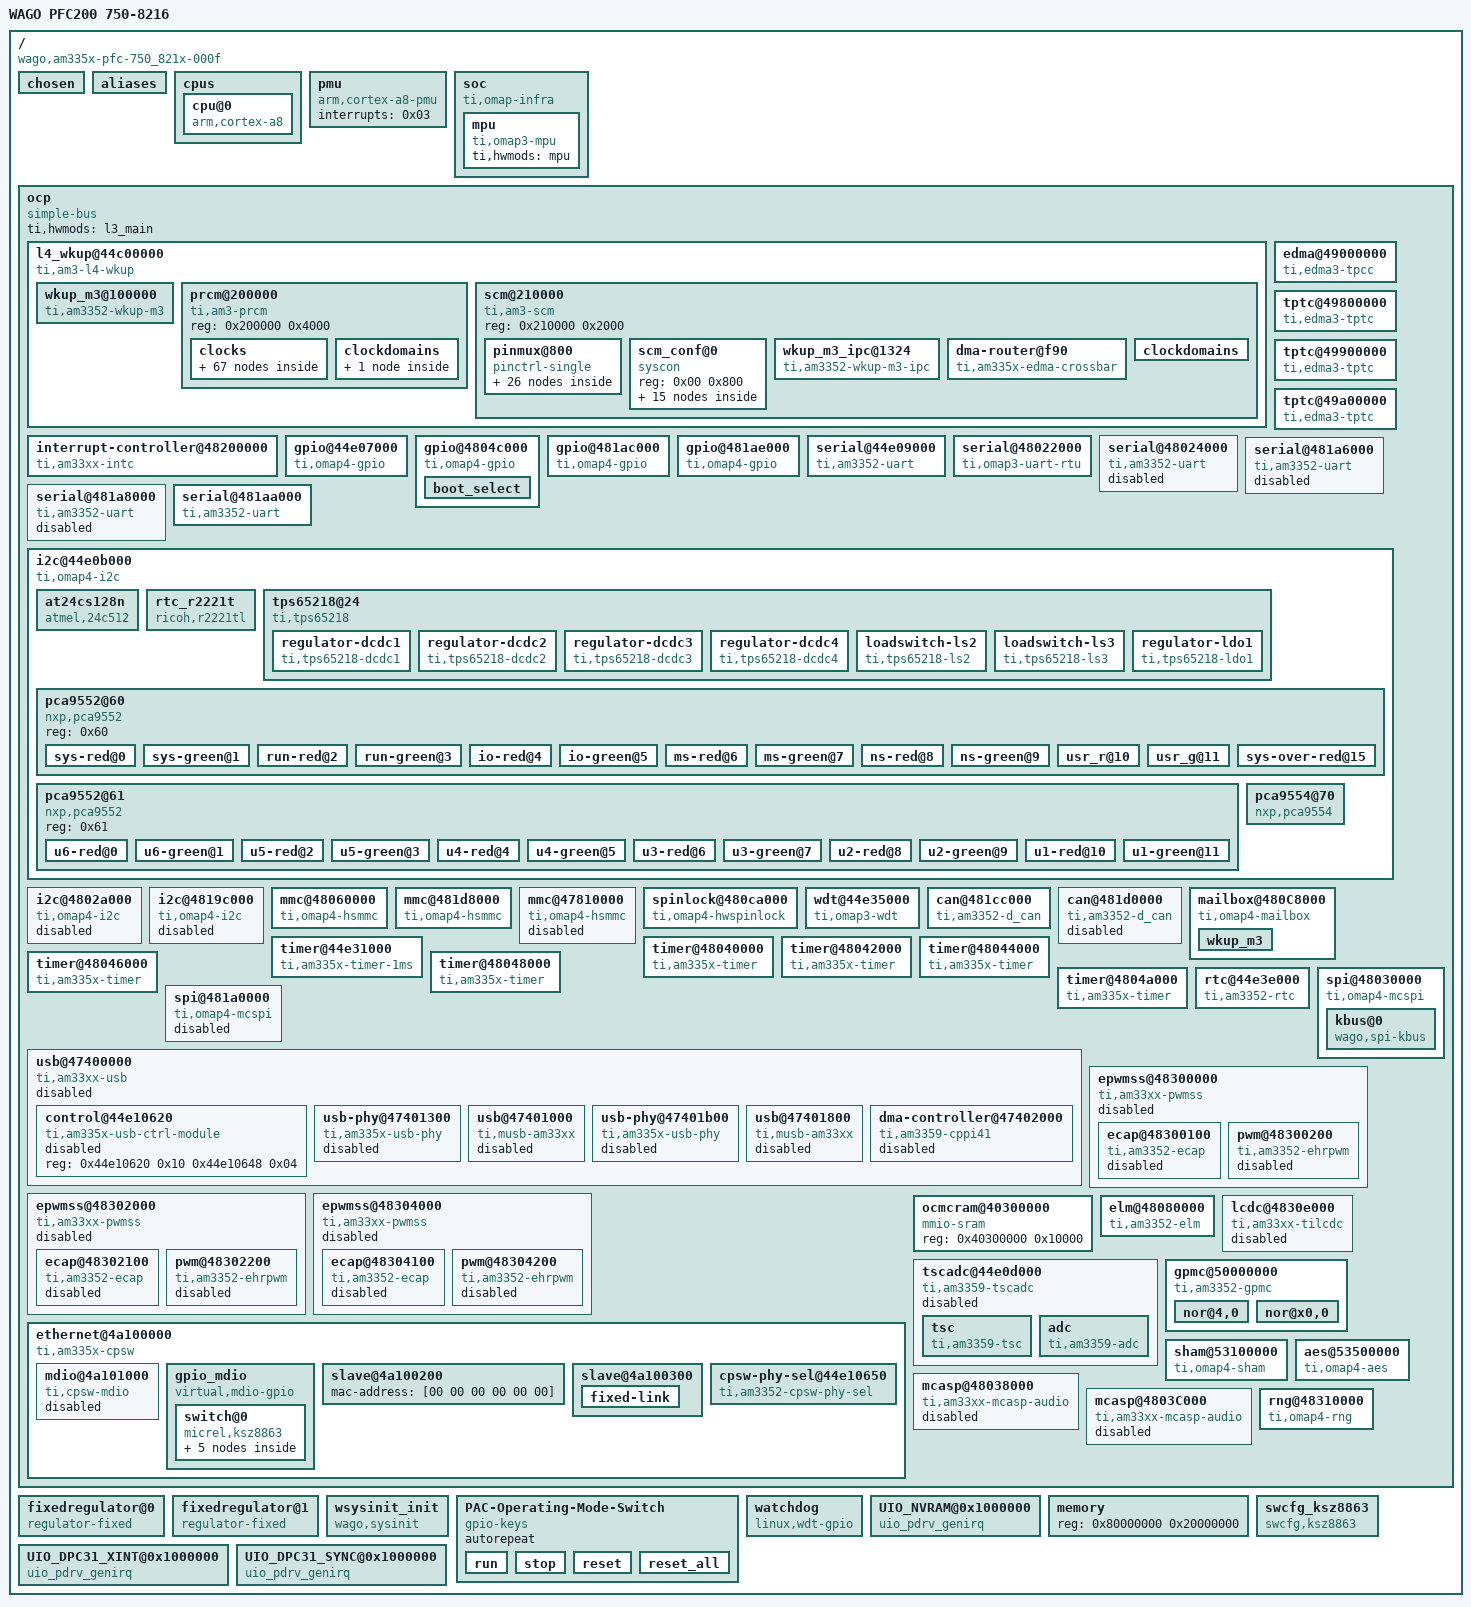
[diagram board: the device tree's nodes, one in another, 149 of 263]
/dts-v1/;

/ {
	compatible = "wago,am335x-pfc-750_821x-000f\0wago,am335x-pfc\0ti,am33xx";
	interrupt-parent = <0x01>;
	#address-cells = <0x01>;
	#size-cells = <0x01>;
	model = "WAGO PFC200 750-8216";

	chosen {
	};

	aliases {
		i2c0 = "/ocp/i2c@44e0b000";
		i2c1 = "/ocp/i2c@4802a000";
		i2c2 = "/ocp/i2c@4819c000";
		serial0 = "/ocp/serial@44e09000";
		serial1 = "/ocp/serial@48022000";
		serial2 = "/ocp/serial@48024000";
		serial3 = "/ocp/serial@481a6000";
		serial4 = "/ocp/serial@481a8000";
		serial5 = "/ocp/serial@481aa000";
		d_can0 = "/ocp/can@481cc000";
		d_can1 = "/ocp/can@481d0000";
		usb0 = "/ocp/usb@47400000/usb@47401000";
		usb1 = "/ocp/usb@47400000/usb@47401800";
		phy0 = "/ocp/usb@47400000/usb-phy@47401300";
		phy1 = "/ocp/usb@47400000/usb-phy@47401b00";
		ethernet0 = "/ocp/ethernet@4a100000/slave@4a100200";
		ethernet1 = "/ocp/ethernet@4a100000/slave@4a100300";
		mdio-gpio0 = "/ocp/ethernet@4a100000/gpio_mdio";
	};

	cpus {
		#address-cells = <0x01>;
		#size-cells = <0x00>;

		cpu@0 {
			compatible = "arm,cortex-a8";
			device_type = "cpu";
			reg = <0x00>;
			operating-points = <0xf4240 0x1437c8 0xc3500 0x1339e0 0xafc80 0x124f80 0x927c0 0x10c8e0 0x493e0 0xe7ef0>;
			voltage-tolerance = <0x02>;
			clocks = <0x02>;
			clock-names = "cpu";
			clock-latency = <0x493e0>;
			cpu0-supply = <0x03>;
		};
	};

	pmu {
		compatible = "arm,cortex-a8-pmu";
		interrupts = <0x03>;
	};

	soc {
		compatible = "ti,omap-infra";

		mpu {
			compatible = "ti,omap3-mpu";
			ti,hwmods = "mpu";
		};
	};

	ocp {
		compatible = "simple-bus";
		#address-cells = <0x01>;
		#size-cells = <0x01>;
		ranges;
		ti,hwmods = "l3_main";

		l4_wkup@44c00000 {
			compatible = "ti,am3-l4-wkup\0simple-bus";
			#address-cells = <0x01>;
			#size-cells = <0x01>;
			ranges = <0x00 0x44c00000 0x280000>;

			wkup_m3@100000 {
				compatible = "ti,am3352-wkup-m3";
				reg = <0x100000 0x4000 0x180000 0x2000>;
				reg-names = "umem\0dmem";
				ti,hwmods = "wkup_m3";
				ti,pm-firmware = "am335x-pm-firmware.elf";
				linux,phandle = <0x27>;
				phandle = <0x27>;
			};

			prcm@200000 {
				compatible = "ti,am3-prcm";
				reg = <0x200000 0x4000>;

				clocks {
					#address-cells = <0x01>;
					#size-cells = <0x00>;

					clk_32768_ck {
						#clock-cells = <0x00>;
						compatible = "fixed-clock";
						clock-frequency = <0x8000>;
						linux,phandle = <0x14>;
						phandle = <0x14>;
					};

					clk_rc32k_ck {
						#clock-cells = <0x00>;
						compatible = "fixed-clock";
						clock-frequency = <0x7d00>;
						linux,phandle = <0x13>;
						phandle = <0x13>;
					};

					virt_19200000_ck {
						#clock-cells = <0x00>;
						compatible = "fixed-clock";
						clock-frequency = <0x124f800>;
						linux,phandle = <0x22>;
						phandle = <0x22>;
					};

					virt_24000000_ck {
						#clock-cells = <0x00>;
						compatible = "fixed-clock";
						clock-frequency = <0x16e3600>;
						linux,phandle = <0x23>;
						phandle = <0x23>;
					};

					virt_25000000_ck {
						#clock-cells = <0x00>;
						compatible = "fixed-clock";
						clock-frequency = <0x17d7840>;
						linux,phandle = <0x24>;
						phandle = <0x24>;
					};

					virt_26000000_ck {
						#clock-cells = <0x00>;
						compatible = "fixed-clock";
						clock-frequency = <0x18cba80>;
						linux,phandle = <0x25>;
						phandle = <0x25>;
					};

					tclkin_ck {
						#clock-cells = <0x00>;
						compatible = "fixed-clock";
						clock-frequency = <0xb71b00>;
						linux,phandle = <0x12>;
						phandle = <0x12>;
					};

					dpll_core_ck@490 {
						#clock-cells = <0x00>;
						compatible = "ti,am3-dpll-core-clock";
						clocks = <0x04 0x04>;
						reg = <0x490 0x45c 0x468>;
						linux,phandle = <0x05>;
						phandle = <0x05>;
					};

					dpll_core_x2_ck {
						#clock-cells = <0x00>;
						compatible = "ti,am3-dpll-x2-clock";
						clocks = <0x05>;
						linux,phandle = <0x06>;
						phandle = <0x06>;
					};

					dpll_core_m4_ck@480 {
						#clock-cells = <0x00>;
						compatible = "ti,divider-clock";
						clocks = <0x06>;
						ti,max-div = <0x1f>;
						reg = <0x480>;
						ti,index-starts-at-one;
						linux,phandle = <0x0e>;
						phandle = <0x0e>;
					};

					dpll_core_m5_ck@484 {
						#clock-cells = <0x00>;
						compatible = "ti,divider-clock";
						clocks = <0x06>;
						ti,max-div = <0x1f>;
						reg = <0x484>;
						ti,index-starts-at-one;
						linux,phandle = <0x16>;
						phandle = <0x16>;
					};

					dpll_core_m6_ck@4d8 {
						#clock-cells = <0x00>;
						compatible = "ti,divider-clock";
						clocks = <0x06>;
						ti,max-div = <0x1f>;
						reg = <0x4d8>;
						ti,index-starts-at-one;
					};

					dpll_mpu_ck@488 {
						#clock-cells = <0x00>;
						compatible = "ti,am3-dpll-clock";
						clocks = <0x04 0x04>;
						reg = <0x488 0x420 0x42c>;
						linux,phandle = <0x02>;
						phandle = <0x02>;
					};

					dpll_mpu_m2_ck@4a8 {
						#clock-cells = <0x00>;
						compatible = "ti,divider-clock";
						clocks = <0x02>;
						ti,max-div = <0x1f>;
						reg = <0x4a8>;
						ti,index-starts-at-one;
					};

					dpll_ddr_ck@494 {
						#clock-cells = <0x00>;
						compatible = "ti,am3-dpll-no-gate-clock";
						clocks = <0x04 0x04>;
						reg = <0x494 0x434 0x440>;
						linux,phandle = <0x07>;
						phandle = <0x07>;
					};

					dpll_ddr_m2_ck@4a0 {
						#clock-cells = <0x00>;
						compatible = "ti,divider-clock";
						clocks = <0x07>;
						ti,max-div = <0x1f>;
						reg = <0x4a0>;
						ti,index-starts-at-one;
						linux,phandle = <0x08>;
						phandle = <0x08>;
					};

					dpll_ddr_m2_div2_ck {
						#clock-cells = <0x00>;
						compatible = "fixed-factor-clock";
						clocks = <0x08>;
						clock-mult = <0x01>;
						clock-div = <0x02>;
					};

					dpll_disp_ck@498 {
						#clock-cells = <0x00>;
						compatible = "ti,am3-dpll-no-gate-clock";
						clocks = <0x04 0x04>;
						reg = <0x498 0x448 0x454>;
						linux,phandle = <0x09>;
						phandle = <0x09>;
					};

					dpll_disp_m2_ck@4a4 {
						#clock-cells = <0x00>;
						compatible = "ti,divider-clock";
						clocks = <0x09>;
						ti,max-div = <0x1f>;
						reg = <0x4a4>;
						ti,index-starts-at-one;
						ti,set-rate-parent;
						linux,phandle = <0x10>;
						phandle = <0x10>;
					};

					dpll_per_ck@48c {
						#clock-cells = <0x00>;
						compatible = "ti,am3-dpll-no-gate-j-type-clock";
						clocks = <0x04 0x04>;
						reg = <0x48c 0x470 0x49c>;
						linux,phandle = <0x0a>;
						phandle = <0x0a>;
					};

					dpll_per_m2_ck@4ac {
						#clock-cells = <0x00>;
						compatible = "ti,divider-clock";
						clocks = <0x0a>;
						ti,max-div = <0x1f>;
						reg = <0x4ac>;
						ti,index-starts-at-one;
						linux,phandle = <0x0b>;
						phandle = <0x0b>;
					};

					dpll_per_m2_div4_wkupdm_ck {
						#clock-cells = <0x00>;
						compatible = "fixed-factor-clock";
						clocks = <0x0b>;
						clock-mult = <0x01>;
						clock-div = <0x04>;
					};

					dpll_per_m2_div4_ck {
						#clock-cells = <0x00>;
						compatible = "fixed-factor-clock";
						clocks = <0x0b>;
						clock-mult = <0x01>;
						clock-div = <0x04>;
					};

					cefuse_fck@a20 {
						#clock-cells = <0x00>;
						compatible = "ti,gate-clock";
						clocks = <0x04>;
						ti,bit-shift = <0x01>;
						reg = <0xa20>;
					};

					clk_24mhz {
						#clock-cells = <0x00>;
						compatible = "fixed-factor-clock";
						clocks = <0x0b>;
						clock-mult = <0x01>;
						clock-div = <0x08>;
						linux,phandle = <0x0c>;
						phandle = <0x0c>;
					};

					clkdiv32k_ck {
						#clock-cells = <0x00>;
						compatible = "fixed-factor-clock";
						clocks = <0x0c>;
						clock-mult = <0x01>;
						clock-div = <0x2dc>;
						linux,phandle = <0x0d>;
						phandle = <0x0d>;
					};

					clkdiv32k_ick@14c {
						#clock-cells = <0x00>;
						compatible = "ti,gate-clock";
						clocks = <0x0d>;
						ti,bit-shift = <0x01>;
						reg = <0x14c>;
						linux,phandle = <0x11>;
						phandle = <0x11>;
					};

					l3_gclk {
						#clock-cells = <0x00>;
						compatible = "fixed-factor-clock";
						clocks = <0x0e>;
						clock-mult = <0x01>;
						clock-div = <0x01>;
						linux,phandle = <0x0f>;
						phandle = <0x0f>;
					};

					pruss_ocp_gclk@530 {
						#clock-cells = <0x00>;
						compatible = "ti,mux-clock";
						clocks = <0x0f 0x10>;
						reg = <0x530>;
					};

					mmu_fck@914 {
						#clock-cells = <0x00>;
						compatible = "ti,gate-clock";
						clocks = <0x0e>;
						ti,bit-shift = <0x01>;
						reg = <0x914>;
					};

					timer1_fck@528 {
						#clock-cells = <0x00>;
						compatible = "ti,mux-clock";
						clocks = <0x04 0x11 0x12 0x13 0x14>;
						reg = <0x528>;
					};

					timer2_fck@508 {
						#clock-cells = <0x00>;
						compatible = "ti,mux-clock";
						clocks = <0x12 0x04 0x11>;
						reg = <0x508>;
					};

					timer3_fck@50c {
						#clock-cells = <0x00>;
						compatible = "ti,mux-clock";
						clocks = <0x12 0x04 0x11>;
						reg = <0x50c>;
					};

					timer4_fck@510 {
						#clock-cells = <0x00>;
						compatible = "ti,mux-clock";
						clocks = <0x12 0x04 0x11>;
						reg = <0x510>;
					};

					timer5_fck@518 {
						#clock-cells = <0x00>;
						compatible = "ti,mux-clock";
						clocks = <0x12 0x04 0x11>;
						reg = <0x518>;
					};

					timer6_fck@51c {
						#clock-cells = <0x00>;
						compatible = "ti,mux-clock";
						clocks = <0x12 0x04 0x11>;
						reg = <0x51c>;
					};

					timer7_fck@504 {
						#clock-cells = <0x00>;
						compatible = "ti,mux-clock";
						clocks = <0x12 0x04 0x11>;
						reg = <0x504>;
					};

					usbotg_fck@47c {
						#clock-cells = <0x00>;
						compatible = "ti,gate-clock";
						clocks = <0x0a>;
						ti,bit-shift = <0x08>;
						reg = <0x47c>;
					};

					dpll_core_m4_div2_ck {
						#clock-cells = <0x00>;
						compatible = "fixed-factor-clock";
						clocks = <0x0e>;
						clock-mult = <0x01>;
						clock-div = <0x02>;
						linux,phandle = <0x15>;
						phandle = <0x15>;
					};

					ieee5000_fck@e4 {
						#clock-cells = <0x00>;
						compatible = "ti,gate-clock";
						clocks = <0x15>;
						ti,bit-shift = <0x01>;
						reg = <0xe4>;
					};

					wdt1_fck@538 {
						#clock-cells = <0x00>;
						compatible = "ti,mux-clock";
						clocks = <0x13 0x11>;
						reg = <0x538>;
					};

					l4_rtc_gclk {
						#clock-cells = <0x00>;
						compatible = "fixed-factor-clock";
						clocks = <0x0e>;
						clock-mult = <0x01>;
						clock-div = <0x02>;
					};

					l4hs_gclk {
						#clock-cells = <0x00>;
						compatible = "fixed-factor-clock";
						clocks = <0x0e>;
						clock-mult = <0x01>;
						clock-div = <0x01>;
					};

					l3s_gclk {
						#clock-cells = <0x00>;
						compatible = "fixed-factor-clock";
						clocks = <0x15>;
						clock-mult = <0x01>;
						clock-div = <0x01>;
					};

					l4fw_gclk {
						#clock-cells = <0x00>;
						compatible = "fixed-factor-clock";
						clocks = <0x15>;
						clock-mult = <0x01>;
						clock-div = <0x01>;
					};

					l4ls_gclk {
						#clock-cells = <0x00>;
						compatible = "fixed-factor-clock";
						clocks = <0x15>;
						clock-mult = <0x01>;
						clock-div = <0x01>;
						linux,phandle = <0x26>;
						phandle = <0x26>;
					};

					sysclk_div_ck {
						#clock-cells = <0x00>;
						compatible = "fixed-factor-clock";
						clocks = <0x0e>;
						clock-mult = <0x01>;
						clock-div = <0x01>;
					};

					cpsw_125mhz_gclk {
						#clock-cells = <0x00>;
						compatible = "fixed-factor-clock";
						clocks = <0x16>;
						clock-mult = <0x01>;
						clock-div = <0x02>;
						linux,phandle = <0x4a>;
						phandle = <0x4a>;
					};

					cpsw_cpts_rft_clk@520 {
						#clock-cells = <0x00>;
						compatible = "ti,mux-clock";
						clocks = <0x16 0x0e>;
						reg = <0x520>;
						linux,phandle = <0x4b>;
						phandle = <0x4b>;
					};

					gpio0_dbclk_mux_ck@53c {
						#clock-cells = <0x00>;
						compatible = "ti,mux-clock";
						clocks = <0x13 0x14 0x11>;
						reg = <0x53c>;
						linux,phandle = <0x17>;
						phandle = <0x17>;
					};

					gpio0_dbclk@408 {
						#clock-cells = <0x00>;
						compatible = "ti,gate-clock";
						clocks = <0x17>;
						ti,bit-shift = <0x12>;
						reg = <0x408>;
					};

					gpio1_dbclk@ac {
						#clock-cells = <0x00>;
						compatible = "ti,gate-clock";
						clocks = <0x11>;
						ti,bit-shift = <0x12>;
						reg = <0xac>;
					};

					gpio2_dbclk@b0 {
						#clock-cells = <0x00>;
						compatible = "ti,gate-clock";
						clocks = <0x11>;
						ti,bit-shift = <0x12>;
						reg = <0xb0>;
					};

					gpio3_dbclk@b4 {
						#clock-cells = <0x00>;
						compatible = "ti,gate-clock";
						clocks = <0x11>;
						ti,bit-shift = <0x12>;
						reg = <0xb4>;
					};

					lcd_gclk@534 {
						#clock-cells = <0x00>;
						compatible = "ti,mux-clock";
						clocks = <0x10 0x16 0x0b>;
						reg = <0x534>;
						ti,set-rate-parent;
						linux,phandle = <0x19>;
						phandle = <0x19>;
					};

					mmc_clk {
						#clock-cells = <0x00>;
						compatible = "fixed-factor-clock";
						clocks = <0x0b>;
						clock-mult = <0x01>;
						clock-div = <0x02>;
					};

					gfx_fclk_clksel_ck@52c {
						#clock-cells = <0x00>;
						compatible = "ti,mux-clock";
						clocks = <0x0e 0x0b>;
						ti,bit-shift = <0x01>;
						reg = <0x52c>;
						linux,phandle = <0x18>;
						phandle = <0x18>;
					};

					gfx_fck_div_ck@52c {
						#clock-cells = <0x00>;
						compatible = "ti,divider-clock";
						clocks = <0x18>;
						reg = <0x52c>;
						ti,max-div = <0x02>;
					};

					sysclkout_pre_ck@700 {
						#clock-cells = <0x00>;
						compatible = "ti,mux-clock";
						clocks = <0x14 0x0f 0x08 0x0b 0x19>;
						reg = <0x700>;
						linux,phandle = <0x1a>;
						phandle = <0x1a>;
					};

					clkout2_div_ck@700 {
						#clock-cells = <0x00>;
						compatible = "ti,divider-clock";
						clocks = <0x1a>;
						ti,bit-shift = <0x03>;
						ti,max-div = <0x08>;
						reg = <0x700>;
						linux,phandle = <0x1f>;
						phandle = <0x1f>;
					};

					dbg_sysclk_ck@414 {
						#clock-cells = <0x00>;
						compatible = "ti,gate-clock";
						clocks = <0x04>;
						ti,bit-shift = <0x13>;
						reg = <0x414>;
						linux,phandle = <0x1b>;
						phandle = <0x1b>;
					};

					dbg_clka_ck@414 {
						#clock-cells = <0x00>;
						compatible = "ti,gate-clock";
						clocks = <0x0e>;
						ti,bit-shift = <0x1e>;
						reg = <0x414>;
						linux,phandle = <0x1c>;
						phandle = <0x1c>;
					};

					stm_pmd_clock_mux_ck@414 {
						#clock-cells = <0x00>;
						compatible = "ti,mux-clock";
						clocks = <0x1b 0x1c>;
						ti,bit-shift = <0x16>;
						reg = <0x414>;
						linux,phandle = <0x1d>;
						phandle = <0x1d>;
					};

					trace_pmd_clk_mux_ck@414 {
						#clock-cells = <0x00>;
						compatible = "ti,mux-clock";
						clocks = <0x1b 0x1c>;
						ti,bit-shift = <0x14>;
						reg = <0x414>;
						linux,phandle = <0x1e>;
						phandle = <0x1e>;
					};

					stm_clk_div_ck@414 {
						#clock-cells = <0x00>;
						compatible = "ti,divider-clock";
						clocks = <0x1d>;
						ti,bit-shift = <0x1b>;
						ti,max-div = <0x40>;
						reg = <0x414>;
						ti,index-power-of-two;
					};

					trace_clk_div_ck@414 {
						#clock-cells = <0x00>;
						compatible = "ti,divider-clock";
						clocks = <0x1e>;
						ti,bit-shift = <0x18>;
						ti,max-div = <0x40>;
						reg = <0x414>;
						ti,index-power-of-two;
					};

					clkout2_ck@700 {
						#clock-cells = <0x00>;
						compatible = "ti,gate-clock";
						clocks = <0x1f>;
						ti,bit-shift = <0x07>;
						reg = <0x700>;
					};
				};

				clockdomains {

					clk_24mhz_clkdm {
						compatible = "ti,clockdomain";
						clocks = <0x11>;
					};
				};
			};

			scm@210000 {
				compatible = "ti,am3-scm\0simple-bus";
				reg = <0x210000 0x2000>;
				#address-cells = <0x01>;
				#size-cells = <0x01>;
				ranges = <0x00 0x210000 0x2000>;

				pinmux@800 {
					compatible = "pinctrl-single";
					reg = <0x800 0x238>;
					#address-cells = <0x01>;
					#size-cells = <0x00>;
					pinctrl-single,register-width = <0x20>;
					pinctrl-single,function-mask = <0x7f>;
					pinctrl-names = "default";
					pinctrl-0 = <0x20 0x21>;

					pinmux_uart0_pins {
						pinctrl-single,pins = <0x170 0x30 0x174 0x50>;
						linux,phandle = <0x2f>;
						phandle = <0x2f>;
					};

					pinmux_spi0_pins {
						pinctrl-single,pins = <0x150 0x60 0x154 0x28 0x158 0x40 0x15c 0x50>;
						linux,phandle = <0x3f>;
						phandle = <0x3f>;
					};

					pinmux_i2c0_pins {
						pinctrl-single,pins = <0x188 0x70 0x18c 0x70>;
						linux,phandle = <0x33>;
						phandle = <0x33>;
					};

					pinmux_gpio_bitbang_mdio_pins {
						pinctrl-single,pins = <0x148 0x37 0x14c 0x17>;
						linux,phandle = <0x50>;
						phandle = <0x50>;
					};

					pinmux_gpio_bitbang_mdio_sleep_pins {
						pinctrl-single,pins = <0x148 0x37 0x14c 0x27>;
						linux,phandle = <0x51>;
						phandle = <0x51>;
					};

					pinmux_gpio3_pins {
						pinctrl-single,pins = <0x194 0x2f 0x198 0x2f 0x19c 0x2f 0x1a0 0x2f 0x1a8 0x37 0x1ac 0x37>;
						linux,phandle = <0x2e>;
						phandle = <0x2e>;
					};

					pinmux_mmc1_pins {
						pinctrl-single,pins = <0x100 0x30 0x104 0x30 0xfc 0x30 0xf8 0x30 0xf4 0x30 0xf0 0x30>;
						linux,phandle = <0x35>;
						phandle = <0x35>;
					};

					pinmux_watchdog_pins {
						pinctrl-single,pins = <0x1e8 0x07>;
						linux,phandle = <0x57>;
						phandle = <0x57>;
					};

					pinmux_uart1_pins {
						pinctrl-single,pins = <0x184 0x48 0x180 0x28 0x178 0x28 0x17c 0x48 0x1a4 0x47>;
						linux,phandle = <0x30>;
						phandle = <0x30>;
					};

					pinmux_uart5_pins {
						pinctrl-single,pins = <0x118 0x4b 0xd8 0x34>;
						linux,phandle = <0x32>;
						phandle = <0x32>;
					};

					pinmux_spi1_pins {
						pinctrl-single,pins = <0x168 0x2c 0x16c 0x44 0x190 0x63 0x164 0x52>;
					};

					pinmux_sdcard_cd_pins {
						pinctrl-single,pins = <0x4c 0x37>;
						linux,phandle = <0x36>;
						phandle = <0x36>;
					};

					pinmux_sdcard_wp_pins {
						pinctrl-single,pins = <0x90 0x37>;
						linux,phandle = <0x37>;
						phandle = <0x37>;
					};

					pinmux_emmc_pins {
						pinctrl-single,pins = <0x80 0x32 0x84 0x32 0x12c 0x34 0x130 0x34 0x134 0x34 0x138 0x34>;
						linux,phandle = <0x3a>;
						phandle = <0x3a>;
					};

					pinmux_gpmc_data_pins {
						pinctrl-single,pins = <0x00 0x60 0x04 0x60 0x08 0x60 0x0c 0x60 0x10 0x60 0x14 0x60 0x18 0x60 0x1c 0x60 0x20 0x60 0x24 0x60 0x28 0x60 0x2c 0x60 0x30 0x60 0x34 0x60 0x38 0x60 0x3c 0x60>;
						linux,phandle = <0x53>;
						phandle = <0x53>;
					};

					pinmux_gpmc_addr_pins {
						pinctrl-single,pins = <0xa0 0x41 0xa4 0x41 0xa8 0x41 0xac 0x41 0xb0 0x41 0xb4 0x41 0xb8 0x41 0xbc 0x41 0xe0 0x41 0xe4 0x41 0xe8 0x41 0xec 0x41 0xc0 0x41 0xc4 0x41 0xc8 0x41 0xcc 0x41 0xd0 0x41 0xd4 0x41>;
						linux,phandle = <0x54>;
						phandle = <0x54>;
					};

					pinmux_gpmc_ctrl_pins {
						pinctrl-single,pins = <0x94 0x50 0x98 0x50 0x70 0x52 0x9c 0x50 0x78 0x50 0x8c 0x32>;
						linux,phandle = <0x55>;
						phandle = <0x55>;
					};

					pinmux_rmii2_pins {
						pinctrl-single,pins = <0x40 0x0b 0x50 0x0b 0x54 0x0b 0x68 0x2b 0x6c 0x2b 0x108 0x29 0x88 0x2a>;
						linux,phandle = <0x4c>;
						phandle = <0x4c>;
					};

					pinmux_rmii2_sleep_pins {
						pinctrl-single,pins = <0x40 0x0b 0x50 0x0b 0x54 0x0b 0x68 0x2b 0x6c 0x2b 0x108 0x29 0x88 0x2a>;
						linux,phandle = <0x4e>;
						phandle = <0x4e>;
					};

					pinmux_rmii1_pins {
						pinctrl-single,pins = <0x144 0x2f 0x114 0x2f 0x128 0x2f 0x124 0x2f 0x140 0x2f 0x13c 0x2f 0x10c 0x2f>;
						linux,phandle = <0x4d>;
						phandle = <0x4d>;
					};

					pinmux_rmii1_sleep_pins {
						pinctrl-single,pins = <0x144 0x2f 0x114 0x2f 0x128 0x2f 0x124 0x2f 0x140 0x2f 0x13c 0x2f 0x10c 0x2f>;
						linux,phandle = <0x4f>;
						phandle = <0x4f>;
					};

					pinmux_kbus_pins {
						pinctrl-single,pins = <0x58 0x37 0x5c 0x37 0x1b4 0x37 0x1e4 0x57 0x60 0x37>;
						linux,phandle = <0x40>;
						phandle = <0x40>;
					};

					pinmux_gpio0_pins {
						pinctrl-single,pins = <0x1b0 0x57>;
						linux,phandle = <0x20>;
						phandle = <0x20>;
					};

					pinmux_gpio1_pins {
						pinctrl-single,pins = <0x44 0x37 0x48 0x57>;
						linux,phandle = <0x21>;
						phandle = <0x21>;
					};

					pinmux_dcan0_pins {
						pinctrl-single,pins = <0x11c 0x01 0x120 0x21>;
						linux,phandle = <0x3d>;
						phandle = <0x3d>;
					};

					pinmux_dpc31_pins {
						pinctrl-single,pins = <0x160 0x2f 0x7c 0x08 0x64 0x2f>;
						linux,phandle = <0x56>;
						phandle = <0x56>;
					};
				};

				scm_conf@0 {
					compatible = "syscon\0simple-bus";
					reg = <0x00 0x800>;
					#address-cells = <0x01>;
					#size-cells = <0x01>;
					ranges = <0x00 0x00 0x800>;
					linux,phandle = <0x3c>;
					phandle = <0x3c>;

					clocks {
						#address-cells = <0x01>;
						#size-cells = <0x00>;

						sys_clkin_ck@40 {
							#clock-cells = <0x00>;
							compatible = "ti,mux-clock";
							clocks = <0x22 0x23 0x24 0x25>;
							ti,bit-shift = <0x16>;
							reg = <0x40>;
							linux,phandle = <0x04>;
							phandle = <0x04>;
						};

						adc_tsc_fck {
							#clock-cells = <0x00>;
							compatible = "fixed-factor-clock";
							clocks = <0x04>;
							clock-mult = <0x01>;
							clock-div = <0x01>;
						};

						dcan0_fck {
							#clock-cells = <0x00>;
							compatible = "fixed-factor-clock";
							clocks = <0x04>;
							clock-mult = <0x01>;
							clock-div = <0x01>;
							linux,phandle = <0x3b>;
							phandle = <0x3b>;
						};

						dcan1_fck {
							#clock-cells = <0x00>;
							compatible = "fixed-factor-clock";
							clocks = <0x04>;
							clock-mult = <0x01>;
							clock-div = <0x01>;
							linux,phandle = <0x3e>;
							phandle = <0x3e>;
						};

						mcasp0_fck {
							#clock-cells = <0x00>;
							compatible = "fixed-factor-clock";
							clocks = <0x04>;
							clock-mult = <0x01>;
							clock-div = <0x01>;
						};

						mcasp1_fck {
							#clock-cells = <0x00>;
							compatible = "fixed-factor-clock";
							clocks = <0x04>;
							clock-mult = <0x01>;
							clock-div = <0x01>;
						};

						smartreflex0_fck {
							#clock-cells = <0x00>;
							compatible = "fixed-factor-clock";
							clocks = <0x04>;
							clock-mult = <0x01>;
							clock-div = <0x01>;
						};

						smartreflex1_fck {
							#clock-cells = <0x00>;
							compatible = "fixed-factor-clock";
							clocks = <0x04>;
							clock-mult = <0x01>;
							clock-div = <0x01>;
						};

						sha0_fck {
							#clock-cells = <0x00>;
							compatible = "fixed-factor-clock";
							clocks = <0x04>;
							clock-mult = <0x01>;
							clock-div = <0x01>;
						};

						aes0_fck {
							#clock-cells = <0x00>;
							compatible = "fixed-factor-clock";
							clocks = <0x04>;
							clock-mult = <0x01>;
							clock-div = <0x01>;
						};

						rng_fck {
							#clock-cells = <0x00>;
							compatible = "fixed-factor-clock";
							clocks = <0x04>;
							clock-mult = <0x01>;
							clock-div = <0x01>;
						};

						ehrpwm0_tbclk@44e10664 {
							#clock-cells = <0x00>;
							compatible = "ti,gate-clock";
							clocks = <0x26>;
							ti,bit-shift = <0x00>;
							reg = <0x664>;
							linux,phandle = <0x47>;
							phandle = <0x47>;
						};

						ehrpwm1_tbclk@44e10664 {
							#clock-cells = <0x00>;
							compatible = "ti,gate-clock";
							clocks = <0x26>;
							ti,bit-shift = <0x01>;
							reg = <0x664>;
							linux,phandle = <0x48>;
							phandle = <0x48>;
						};

						ehrpwm2_tbclk@44e10664 {
							#clock-cells = <0x00>;
							compatible = "ti,gate-clock";
							clocks = <0x26>;
							ti,bit-shift = <0x02>;
							reg = <0x664>;
							linux,phandle = <0x49>;
							phandle = <0x49>;
						};
					};
				};

				wkup_m3_ipc@1324 {
					compatible = "ti,am3352-wkup-m3-ipc";
					reg = <0x1324 0x24>;
					interrupts = <0x4e>;
					ti,rproc = <0x27>;
					mboxes = <0x28 0x29>;
				};

				dma-router@f90 {
					compatible = "ti,am335x-edma-crossbar";
					reg = <0xf90 0x40>;
					#dma-cells = <0x03>;
					dma-requests = <0x20>;
					dma-masters = <0x2a>;
					linux,phandle = <0x34>;
					phandle = <0x34>;
				};

				clockdomains {
				};
			};
		};

		interrupt-controller@48200000 {
			compatible = "ti,am33xx-intc";
			interrupt-controller;
			#interrupt-cells = <0x01>;
			reg = <0x48200000 0x1000>;
			linux,phandle = <0x01>;
			phandle = <0x01>;
		};

		edma@49000000 {
			compatible = "ti,edma3-tpcc";
			ti,hwmods = "tpcc";
			reg = <0x49000000 0x10000>;
			reg-names = "edma3_cc";
			interrupts = <0x0c 0x0d 0x0e>;
			interrupt-names = "edma3_ccint\0edma3_mperr\0edma3_ccerrint";
			dma-requests = <0x40>;
			#dma-cells = <0x02>;
			ti,tptcs = <0x2b 0x07 0x2c 0x05 0x2d 0x00>;
			ti,edma-memcpy-channels = <0x14 0x15>;
			linux,phandle = <0x2a>;
			phandle = <0x2a>;
		};

		tptc@49800000 {
			compatible = "ti,edma3-tptc";
			ti,hwmods = "tptc0";
			reg = <0x49800000 0x100000>;
			interrupts = <0x70>;
			interrupt-names = "edma3_tcerrint";
			linux,phandle = <0x2b>;
			phandle = <0x2b>;
		};

		tptc@49900000 {
			compatible = "ti,edma3-tptc";
			ti,hwmods = "tptc1";
			reg = <0x49900000 0x100000>;
			interrupts = <0x71>;
			interrupt-names = "edma3_tcerrint";
			linux,phandle = <0x2c>;
			phandle = <0x2c>;
		};

		tptc@49a00000 {
			compatible = "ti,edma3-tptc";
			ti,hwmods = "tptc2";
			reg = <0x49a00000 0x100000>;
			interrupts = <0x72>;
			interrupt-names = "edma3_tcerrint";
			linux,phandle = <0x2d>;
			phandle = <0x2d>;
		};

		gpio@44e07000 {
			compatible = "ti,omap4-gpio";
			ti,hwmods = "gpio1";
			gpio-controller;
			#gpio-cells = <0x02>;
			interrupt-controller;
			#interrupt-cells = <0x02>;
			reg = <0x44e07000 0x1000>;
			interrupts = <0x60>;
			linux,phandle = <0x42>;
			phandle = <0x42>;
		};

		gpio@4804c000 {
			compatible = "ti,omap4-gpio";
			ti,hwmods = "gpio2";
			gpio-controller;
			#gpio-cells = <0x02>;
			interrupt-controller;
			#interrupt-cells = <0x02>;
			reg = <0x4804c000 0x1000>;
			interrupts = <0x62>;
			linux,phandle = <0x39>;
			phandle = <0x39>;

			boot_select {
				gpio-hog;
				gpios = <0x12 0x01>;
				output-high;
				line-name = "boot_select";
			};
		};

		gpio@481ac000 {
			compatible = "ti,omap4-gpio";
			ti,hwmods = "gpio3";
			gpio-controller;
			#gpio-cells = <0x02>;
			interrupt-controller;
			#interrupt-cells = <0x02>;
			reg = <0x481ac000 0x1000>;
			interrupts = <0x20>;
		};

		gpio@481ae000 {
			compatible = "ti,omap4-gpio";
			ti,hwmods = "gpio4";
			gpio-controller;
			#gpio-cells = <0x02>;
			interrupt-controller;
			#interrupt-cells = <0x02>;
			reg = <0x481ae000 0x1000>;
			interrupts = <0x3e>;
			pinctrl-names = "default";
			pinctrl-0 = <0x2e>;
			linux,phandle = <0x31>;
			phandle = <0x31>;
		};

		serial@44e09000 {
			compatible = "ti,am3352-uart\0ti,omap3-uart";
			ti,hwmods = "uart1";
			clock-frequency = <0x2dc6c00>;
			reg = <0x44e09000 0x2000>;
			interrupts = <0x48>;
			status = "okay";
			dmas = <0x2a 0x1a 0x00 0x2a 0x1b 0x00>;
			dma-names = "tx\0rx";
			pinctrl-names = "default";
			pinctrl-0 = <0x2f>;
		};

		serial@48022000 {
			compatible = "ti,omap3-uart-rtu";
			ti,hwmods = "uart2";
			clock-frequency = <0x2dc6c00>;
			reg = <0x48022000 0x2000>;
			interrupts = <0x49>;
			status = "okay";
			dmas = <0x2a 0x1c 0x00 0x2a 0x1d 0x00>;
			dma-names = "tx\0rx";
			pinctrl-names = "default";
			pinctrl-0 = <0x30>;
			rs485en-gpio = <0x31 0x13 0x01>;
			rs485-rts-active-high;
			rs485-rts-delay = <0x01 0x01>;
		};

		serial@48024000 {
			compatible = "ti,am3352-uart\0ti,omap3-uart";
			ti,hwmods = "uart3";
			clock-frequency = <0x2dc6c00>;
			reg = <0x48024000 0x2000>;
			interrupts = <0x4a>;
			status = "disabled";
			dmas = <0x2a 0x1e 0x00 0x2a 0x1f 0x00>;
			dma-names = "tx\0rx";
		};

		serial@481a6000 {
			compatible = "ti,am3352-uart\0ti,omap3-uart";
			ti,hwmods = "uart4";
			clock-frequency = <0x2dc6c00>;
			reg = <0x481a6000 0x2000>;
			interrupts = <0x2c>;
			status = "disabled";
		};

		serial@481a8000 {
			compatible = "ti,am3352-uart\0ti,omap3-uart";
			ti,hwmods = "uart5";
			clock-frequency = <0x2dc6c00>;
			reg = <0x481a8000 0x2000>;
			interrupts = <0x2d>;
			status = "disabled";
		};

		serial@481aa000 {
			compatible = "ti,am3352-uart\0ti,omap3-uart";
			ti,hwmods = "uart6";
			clock-frequency = <0x2dc6c00>;
			reg = <0x481aa000 0x2000>;
			interrupts = <0x2e>;
			status = "okay";
			pinctrl-names = "default";
			pinctrl-0 = <0x32>;
		};

		i2c@44e0b000 {
			compatible = "ti,omap4-i2c";
			#address-cells = <0x01>;
			#size-cells = <0x00>;
			ti,hwmods = "i2c1";
			reg = <0x44e0b000 0x1000>;
			interrupts = <0x46>;
			status = "okay";
			pinctrl-names = "default";
			pinctrl-0 = <0x33>;
			clock-frequency = <0x186a0>;

			at24cs128n {
				compatible = "atmel,24c512";
				reg = <0x54>;
				pagesize = <0x80>;
			};

			rtc_r2221t {
				compatible = "ricoh,r2221tl";
				reg = <0x32>;
				interrupt-parent = <0x31>;
				interrupts = <0x15 0x08>;
				trim-data = <0x00 0x01 0x1f>;
			};

			tps65218@24 {
				compatible = "ti,tps65218";
				reg = <0x24>;
				interrupt-controller;
				strict-supply-voltage = <0x01>;
				under-voltage-hysteresis = <0x61a80>;
				under-voltage-limit = <0x331df0>;
				#interrupt-cells = <0x02>;
				interrupt-parent = <0x31>;
				interrupts = <0x14 0x08>;

				regulator-dcdc1 {
					compatible = "ti,tps65218-dcdc1";
					regulator-name = "vdd_CORE";
					regulator-min-microvolt = <0x10c8e0>;
					regulator-max-microvolt = <0x10c8e0>;
					regulator-boot-on;
					regulator-always-on;
				};

				regulator-dcdc2 {
					compatible = "ti,tps65218-dcdc2";
					regulator-name = "vdd_MPU";
					regulator-min-microvolt = <0xdea80>;
					regulator-max-microvolt = <0x1506d0>;
					regulator-boot-on;
					regulator-always-on;
					linux,phandle = <0x03>;
					phandle = <0x03>;
				};

				regulator-dcdc3 {
					compatible = "ti,tps65218-dcdc3";
					regulator-name = "vdd_DDR";
					regulator-min-microvolt = <0x16e360>;
					regulator-max-microvolt = <0x16e360>;
					regulator-boot-on;
					regulator-always-on;
				};

				regulator-dcdc4 {
					compatible = "ti,tps65218-dcdc4";
					regulator-name = "vdd_LOGIC";
					regulator-min-microvolt = <0x325aa0>;
					regulator-max-microvolt = <0x325aa0>;
					regulator-boot-on;
					regulator-always-on;
					linux,phandle = <0x38>;
					phandle = <0x38>;
				};

				loadswitch-ls2 {
					compatible = "ti,tps65218-ls2";
					regulator-name = "vdd_LS2_USB";
					regulator-min-microamp = <0x30d40>;
					regulator-max-microamp = <0x30d40>;
					regulator-boot-on;
					regulator-always-on;
				};

				loadswitch-ls3 {
					compatible = "ti,tps65218-ls3";
					regulator-name = "vdd_LS3_FPGA_ETHERNET";
					regulator-min-microamp = <0xf4240>;
					regulator-max-microamp = <0xf4240>;
					regulator-boot-on;
					regulator-always-on;
				};

				regulator-ldo1 {
					compatible = "ti,tps65218-ldo1";
					regulator-name = "ldo1";
					regulator-always-on;
				};
			};

			pca9552@60 {
				compatible = "nxp,pca9552";
				#address-cells = <0x01>;
				#size-cells = <0x00>;
				reg = <0x60>;

				sys-red@0 {
					label = "sys-red";
					reg = <0x00>;
					linux,default-trigger = "timer";
				};

				sys-green@1 {
					label = "sys-green";
					reg = <0x01>;
					linux,default-trigger = "timer";
				};

				run-red@2 {
					label = "run-red";
					reg = <0x02>;
				};

				run-green@3 {
					label = "run-green";
					reg = <0x03>;
				};

				io-red@4 {
					label = "io-red";
					reg = <0x04>;
				};

				io-green@5 {
					label = "io-green";
					reg = <0x05>;
				};

				ms-red@6 {
					label = "ms-red";
					reg = <0x06>;
				};

				ms-green@7 {
					label = "ms-green";
					reg = <0x07>;
				};

				ns-red@8 {
					label = "ns-red";
					reg = <0x08>;
				};

				ns-green@9 {
					label = "ns-green";
					reg = <0x09>;
				};

				usr_r@10 {
					label = "can-red";
					reg = <0x0a>;
				};

				usr_g@11 {
					label = "can-green";
					reg = <0x0b>;
				};

				sys-over-red@15 {
					label = "sys-over-red";
					reg = <0x0f>;
					linux,default-trigger = "default-on";
				};
			};

			pca9552@61 {
				compatible = "nxp,pca9552";
				#address-cells = <0x01>;
				#size-cells = <0x00>;
				reg = <0x61>;

				u6-red@0 {
					label = "bf-red";
					reg = <0x00>;
				};

				u6-green@1 {
					label = "bf-green";
					reg = <0x01>;
				};

				u5-red@2 {
					label = "dia-red";
					reg = <0x02>;
				};

				u5-green@3 {
					label = "dia-green";
					reg = <0x03>;
				};

				u4-red@4 {
					label = "u4-red";
					reg = <0x04>;
				};

				u4-green@5 {
					label = "u4-green";
					reg = <0x05>;
				};

				u3-red@6 {
					label = "u3-red";
					reg = <0x06>;
				};

				u3-green@7 {
					label = "u3-green";
					reg = <0x07>;
				};

				u2-red@8 {
					label = "u2-red";
					reg = <0x08>;
				};

				u2-green@9 {
					label = "u2-green";
					reg = <0x09>;
				};

				u1-red@10 {
					label = "u1-red";
					reg = <0x0a>;
				};

				u1-green@11 {
					label = "u1-green";
					reg = <0x0b>;
				};
			};

			pca9554@70 {
				compatible = "nxp,pca9554";
				#address-cells = <0x01>;
				#size-cells = <0x00>;
				#gpio-cells = <0x02>;
				gpio-controller;
				reg = <0x70>;
				linux,phandle = <0x41>;
				phandle = <0x41>;
			};
		};

		i2c@4802a000 {
			compatible = "ti,omap4-i2c";
			#address-cells = <0x01>;
			#size-cells = <0x00>;
			ti,hwmods = "i2c2";
			reg = <0x4802a000 0x1000>;
			interrupts = <0x47>;
			status = "disabled";
		};

		i2c@4819c000 {
			compatible = "ti,omap4-i2c";
			#address-cells = <0x01>;
			#size-cells = <0x00>;
			ti,hwmods = "i2c3";
			reg = <0x4819c000 0x1000>;
			interrupts = <0x1e>;
			status = "disabled";
		};

		mmc@48060000 {
			compatible = "ti,omap4-hsmmc";
			ti,hwmods = "mmc1";
			ti,dual-volt;
			ti,needs-special-reset;
			ti,needs-special-hs-handling;
			dmas = <0x34 0x18 0x00 0x00 0x34 0x19 0x00 0x00>;
			dma-names = "tx\0rx";
			interrupts = <0x40>;
			interrupt-parent = <0x01>;
			reg = <0x48060000 0x1000>;
			status = "okay";
			pinctrl-names = "default";
			pinctrl-0 = <0x35 0x36 0x37>;
			vmmc-supply = <0x38>;
			bus-width = <0x04>;
			cd-gpios = <0x39 0x13 0x01>;
		};

		mmc@481d8000 {
			compatible = "ti,omap4-hsmmc";
			ti,hwmods = "mmc2";
			ti,needs-special-reset;
			dmas = <0x2a 0x02 0x00 0x2a 0x03 0x00>;
			dma-names = "tx\0rx";
			interrupts = <0x1c>;
			interrupt-parent = <0x01>;
			reg = <0x481d8000 0x1000>;
			status = "okay";
			pinctrl-names = "default";
			pinctrl-0 = <0x3a>;
			vmmc-supply = <0x38>;
			bus-width = <0x04>;
			ti,non-removable;
		};

		mmc@47810000 {
			compatible = "ti,omap4-hsmmc";
			ti,hwmods = "mmc3";
			ti,needs-special-reset;
			interrupts = <0x1d>;
			interrupt-parent = <0x01>;
			reg = <0x47810000 0x1000>;
			status = "disabled";
		};

		spinlock@480ca000 {
			compatible = "ti,omap4-hwspinlock";
			reg = <0x480ca000 0x1000>;
			ti,hwmods = "spinlock";
			#hwlock-cells = <0x01>;
		};

		wdt@44e35000 {
			compatible = "ti,omap3-wdt";
			ti,hwmods = "wd_timer2";
			reg = <0x44e35000 0x1000>;
			interrupts = <0x5b>;
		};

		can@481cc000 {
			compatible = "ti,am3352-d_can";
			ti,hwmods = "d_can0";
			reg = <0x481cc000 0x2000>;
			clocks = <0x3b>;
			clock-names = "fck";
			syscon-raminit = <0x3c 0x644 0x00>;
			interrupts = <0x34>;
			status = "okay";
			pinctrl-names = "default";
			pinctrl-0 = <0x3d>;
		};

		can@481d0000 {
			compatible = "ti,am3352-d_can";
			ti,hwmods = "d_can1";
			reg = <0x481d0000 0x2000>;
			clocks = <0x3e>;
			clock-names = "fck";
			syscon-raminit = <0x3c 0x644 0x01>;
			interrupts = <0x37>;
			status = "disabled";
		};

		mailbox@480C8000 {
			compatible = "ti,omap4-mailbox";
			reg = <0x480c8000 0x200>;
			interrupts = <0x4d>;
			ti,hwmods = "mailbox";
			#mbox-cells = <0x01>;
			ti,mbox-num-users = <0x04>;
			ti,mbox-num-fifos = <0x08>;
			linux,phandle = <0x28>;
			phandle = <0x28>;

			wkup_m3 {
				ti,mbox-send-noirq;
				ti,mbox-tx = <0x00 0x00 0x00>;
				ti,mbox-rx = <0x00 0x00 0x03>;
				linux,phandle = <0x29>;
				phandle = <0x29>;
			};
		};

		timer@44e31000 {
			compatible = "ti,am335x-timer-1ms";
			reg = <0x44e31000 0x400>;
			interrupts = <0x43>;
			ti,hwmods = "timer1";
			ti,timer-alwon;
		};

		timer@48040000 {
			compatible = "ti,am335x-timer";
			reg = <0x48040000 0x400>;
			interrupts = <0x44>;
			ti,hwmods = "timer2";
		};

		timer@48042000 {
			compatible = "ti,am335x-timer";
			reg = <0x48042000 0x400>;
			interrupts = <0x45>;
			ti,hwmods = "timer3";
		};

		timer@48044000 {
			compatible = "ti,am335x-timer";
			reg = <0x48044000 0x400>;
			interrupts = <0x5c>;
			ti,hwmods = "timer4";
			ti,timer-pwm;
		};

		timer@48046000 {
			compatible = "ti,am335x-timer";
			reg = <0x48046000 0x400>;
			interrupts = <0x5d>;
			ti,hwmods = "timer5";
			ti,timer-pwm;
		};

		timer@48048000 {
			compatible = "ti,am335x-timer";
			reg = <0x48048000 0x400>;
			interrupts = <0x5e>;
			ti,hwmods = "timer6";
			ti,timer-pwm;
		};

		timer@4804a000 {
			compatible = "ti,am335x-timer";
			reg = <0x4804a000 0x400>;
			interrupts = <0x5f>;
			ti,hwmods = "timer7";
			ti,timer-pwm;
		};

		rtc@44e3e000 {
			compatible = "ti,am3352-rtc\0ti,da830-rtc";
			reg = <0x44e3e000 0x1000>;
			interrupts = <0x4b 0x4c>;
			ti,hwmods = "rtc";
		};

		spi@48030000 {
			compatible = "ti,omap4-mcspi";
			#address-cells = <0x01>;
			#size-cells = <0x00>;
			reg = <0x48030000 0x400>;
			interrupts = <0x41>;
			ti,spi-num-cs = <0x02>;
			ti,hwmods = "spi0";
			dmas = <0x2a 0x10 0x00 0x2a 0x11 0x00 0x2a 0x12 0x00 0x2a 0x13 0x00>;
			dma-names = "tx0\0rx0\0tx1\0rx1";
			status = "okay";
			pinctrl-names = "default";
			pinctrl-0 = <0x3f>;
			spi-rt;
			spi-rt-prio = <0x51>;

			kbus@0 {
				compatible = "wago,spi-kbus";
				reg = <0x00>;
				spi-max-frequency = <0x989680>;
				kbus,dma-boost;
				kbus,dma-boost-prio = <0x55>;
				kbus,dma-boost-irq-thread = "irq/20-49000000";
				kbus,dma-default-prio = <0x32>;
				status = "okay";
				pinctrl-names = "default";
				pinctrl-0 = <0x40>;
				kbus,tty-device = "ttyO5";
				kbus,gpio-nrst = <0x41 0x03 0x00>;
				kbus,gpio-nsync = <0x39 0x16 0x00>;
				kbus,gpio-cmdsel = <0x31 0x07 0x00>;
				kbus,gpio-nirq = <0x39 0x17 0x00>;
				kbus,gpio-nerr = <0x39 0x18 0x00>;
				kbus,gpio-nrdy = <0x42 0x14 0x00>;
			};
		};

		spi@481a0000 {
			compatible = "ti,omap4-mcspi";
			#address-cells = <0x01>;
			#size-cells = <0x00>;
			reg = <0x481a0000 0x400>;
			interrupts = <0x7d>;
			ti,spi-num-cs = <0x02>;
			ti,hwmods = "spi1";
			dmas = <0x2a 0x2a 0x00 0x2a 0x2b 0x00 0x2a 0x2c 0x00 0x2a 0x2d 0x00>;
			dma-names = "tx0\0rx0\0tx1\0rx1";
			status = "disabled";
		};

		usb@47400000 {
			compatible = "ti,am33xx-usb";
			reg = <0x47400000 0x1000>;
			ranges;
			#address-cells = <0x01>;
			#size-cells = <0x01>;
			ti,hwmods = "usb_otg_hs";
			status = "disabled";

			control@44e10620 {
				compatible = "ti,am335x-usb-ctrl-module";
				reg = <0x44e10620 0x10 0x44e10648 0x04>;
				reg-names = "phy_ctrl\0wakeup";
				status = "disabled";
				linux,phandle = <0x43>;
				phandle = <0x43>;
			};

			usb-phy@47401300 {
				compatible = "ti,am335x-usb-phy";
				reg = <0x47401300 0x100>;
				reg-names = "phy";
				status = "disabled";
				ti,ctrl_mod = <0x43>;
				linux,phandle = <0x44>;
				phandle = <0x44>;
			};

			usb@47401000 {
				compatible = "ti,musb-am33xx";
				status = "disabled";
				reg = <0x47401400 0x400 0x47401000 0x200>;
				reg-names = "mc\0control";
				interrupts = <0x12>;
				interrupt-names = "mc";
				dr_mode = "otg";
				mentor,multipoint = <0x01>;
				mentor,num-eps = <0x10>;
				mentor,ram-bits = <0x0c>;
				mentor,power = <0x1f4>;
				phys = <0x44>;
				dmas = <0x45 0x00 0x00 0x45 0x01 0x00 0x45 0x02 0x00 0x45 0x03 0x00 0x45 0x04 0x00 0x45 0x05 0x00 0x45 0x06 0x00 0x45 0x07 0x00 0x45 0x08 0x00 0x45 0x09 0x00 0x45 0x0a 0x00 0x45 0x0b 0x00 0x45 0x0c 0x00 0x45 0x0d 0x00 0x45 0x0e 0x00 0x45 0x00 0x01 0x45 0x01 0x01 0x45 0x02 0x01 0x45 0x03 0x01 0x45 0x04 0x01 0x45 0x05 0x01 0x45 0x06 0x01 0x45 0x07 0x01 0x45 0x08 0x01 0x45 0x09 0x01 0x45 0x0a 0x01 0x45 0x0b 0x01 0x45 0x0c 0x01 0x45 0x0d 0x01 0x45 0x0e 0x01>;
				dma-names = "rx1\0rx2\0rx3\0rx4\0rx5\0rx6\0rx7\0rx8\0rx9\0rx10\0rx11\0rx12\0rx13\0rx14\0rx15\0tx1\0tx2\0tx3\0tx4\0tx5\0tx6\0tx7\0tx8\0tx9\0tx10\0tx11\0tx12\0tx13\0tx14\0tx15";
			};

			usb-phy@47401b00 {
				compatible = "ti,am335x-usb-phy";
				reg = <0x47401b00 0x100>;
				reg-names = "phy";
				status = "disabled";
				ti,ctrl_mod = <0x43>;
				linux,phandle = <0x46>;
				phandle = <0x46>;
			};

			usb@47401800 {
				compatible = "ti,musb-am33xx";
				status = "disabled";
				reg = <0x47401c00 0x400 0x47401800 0x200>;
				reg-names = "mc\0control";
				interrupts = <0x13>;
				interrupt-names = "mc";
				dr_mode = "otg";
				mentor,multipoint = <0x01>;
				mentor,num-eps = <0x10>;
				mentor,ram-bits = <0x0c>;
				mentor,power = <0x1f4>;
				phys = <0x46>;
				dmas = <0x45 0x0f 0x00 0x45 0x10 0x00 0x45 0x11 0x00 0x45 0x12 0x00 0x45 0x13 0x00 0x45 0x14 0x00 0x45 0x15 0x00 0x45 0x16 0x00 0x45 0x17 0x00 0x45 0x18 0x00 0x45 0x19 0x00 0x45 0x1a 0x00 0x45 0x1b 0x00 0x45 0x1c 0x00 0x45 0x1d 0x00 0x45 0x0f 0x01 0x45 0x10 0x01 0x45 0x11 0x01 0x45 0x12 0x01 0x45 0x13 0x01 0x45 0x14 0x01 0x45 0x15 0x01 0x45 0x16 0x01 0x45 0x17 0x01 0x45 0x18 0x01 0x45 0x19 0x01 0x45 0x1a 0x01 0x45 0x1b 0x01 0x45 0x1c 0x01 0x45 0x1d 0x01>;
				dma-names = "rx1\0rx2\0rx3\0rx4\0rx5\0rx6\0rx7\0rx8\0rx9\0rx10\0rx11\0rx12\0rx13\0rx14\0rx15\0tx1\0tx2\0tx3\0tx4\0tx5\0tx6\0tx7\0tx8\0tx9\0tx10\0tx11\0tx12\0tx13\0tx14\0tx15";
			};

			dma-controller@47402000 {
				compatible = "ti,am3359-cppi41";
				reg = <0x47400000 0x1000 0x47402000 0x1000 0x47403000 0x1000 0x47404000 0x4000>;
				reg-names = "glue\0controller\0scheduler\0queuemgr";
				interrupts = <0x11>;
				interrupt-names = "glue";
				#dma-cells = <0x02>;
				#dma-channels = <0x1e>;
				#dma-requests = <0x100>;
				status = "disabled";
				linux,phandle = <0x45>;
				phandle = <0x45>;
			};
		};

		epwmss@48300000 {
			compatible = "ti,am33xx-pwmss";
			reg = <0x48300000 0x10>;
			ti,hwmods = "epwmss0";
			#address-cells = <0x01>;
			#size-cells = <0x01>;
			status = "disabled";
			ranges = <0x48300100 0x48300100 0x80 0x48300180 0x48300180 0x80 0x48300200 0x48300200 0x80>;

			ecap@48300100 {
				compatible = "ti,am3352-ecap\0ti,am33xx-ecap";
				#pwm-cells = <0x03>;
				reg = <0x48300100 0x80>;
				clocks = <0x26>;
				clock-names = "fck";
				interrupts = <0x1f>;
				interrupt-names = "ecap0";
				status = "disabled";
			};

			pwm@48300200 {
				compatible = "ti,am3352-ehrpwm\0ti,am33xx-ehrpwm";
				#pwm-cells = <0x03>;
				reg = <0x48300200 0x80>;
				clocks = <0x47 0x26>;
				clock-names = "tbclk\0fck";
				status = "disabled";
			};
		};

		epwmss@48302000 {
			compatible = "ti,am33xx-pwmss";
			reg = <0x48302000 0x10>;
			ti,hwmods = "epwmss1";
			#address-cells = <0x01>;
			#size-cells = <0x01>;
			status = "disabled";
			ranges = <0x48302100 0x48302100 0x80 0x48302180 0x48302180 0x80 0x48302200 0x48302200 0x80>;

			ecap@48302100 {
				compatible = "ti,am3352-ecap\0ti,am33xx-ecap";
				#pwm-cells = <0x03>;
				reg = <0x48302100 0x80>;
				clocks = <0x26>;
				clock-names = "fck";
				interrupts = <0x2f>;
				interrupt-names = "ecap1";
				status = "disabled";
			};

			pwm@48302200 {
				compatible = "ti,am3352-ehrpwm\0ti,am33xx-ehrpwm";
				#pwm-cells = <0x03>;
				reg = <0x48302200 0x80>;
				clocks = <0x48 0x26>;
				clock-names = "tbclk\0fck";
				status = "disabled";
			};
		};

		epwmss@48304000 {
			compatible = "ti,am33xx-pwmss";
			reg = <0x48304000 0x10>;
			ti,hwmods = "epwmss2";
			#address-cells = <0x01>;
			#size-cells = <0x01>;
			status = "disabled";
			ranges = <0x48304100 0x48304100 0x80 0x48304180 0x48304180 0x80 0x48304200 0x48304200 0x80>;

			ecap@48304100 {
				compatible = "ti,am3352-ecap\0ti,am33xx-ecap";
				#pwm-cells = <0x03>;
				reg = <0x48304100 0x80>;
				clocks = <0x26>;
				clock-names = "fck";
				interrupts = <0x3d>;
				interrupt-names = "ecap2";
				status = "disabled";
			};

			pwm@48304200 {
				compatible = "ti,am3352-ehrpwm\0ti,am33xx-ehrpwm";
				#pwm-cells = <0x03>;
				reg = <0x48304200 0x80>;
				clocks = <0x49 0x26>;
				clock-names = "tbclk\0fck";
				status = "disabled";
			};
		};

		ethernet@4a100000 {
			compatible = "ti,am335x-cpsw\0ti,cpsw";
			ti,hwmods = "cpgmac0";
			clocks = <0x4a 0x4b>;
			clock-names = "fck\0cpts";
			cpdma_channels = <0x08>;
			ale_entries = <0x400>;
			bd_ram_size = <0x2000>;
			no_bd_ram = <0x00>;
			mac_control = <0x18021>;
			slaves = <0x02>;
			active_slave = <0x01>;
			cpts_clock_mult = <0x80000000>;
			cpts_clock_shift = <0x1d>;
			reg = <0x4a100000 0x800 0x4a101200 0x100>;
			#address-cells = <0x01>;
			#size-cells = <0x01>;
			interrupt-parent = <0x01>;
			interrupts = <0x28 0x29 0x2a 0x2b>;
			ranges;
			syscon = <0x3c>;
			status = "okay";
			pinctrl-names = "default\0sleep";
			pinctrl-0 = <0x4c 0x4d>;
			pinctrl-1 = <0x4e 0x4f>;
			linux,phandle = <0x52>;
			phandle = <0x52>;

			mdio@4a101000 {
				compatible = "ti,cpsw-mdio\0ti,davinci_mdio";
				#address-cells = <0x01>;
				#size-cells = <0x00>;
				ti,hwmods = "davinci_mdio";
				bus_freq = <0xf4240>;
				reg = <0x4a101000 0x100>;
				status = "disabled";
			};

			gpio_mdio {
				compatible = "virtual,mdio-gpio";
				#address-cells = <0x01>;
				#size-cells = <0x00>;
				status = "okay";
				pinctrl-names = "default\0sleep";
				pinctrl-0 = <0x50>;
				pinctrl-1 = <0x51>;
				gpios = <0x42 0x01 0x00 0x42 0x00 0x00>;
				linux,phandle = <0x58>;
				phandle = <0x58>;

				switch@0 {
					compatible = "micrel,ksz8863";
					#address-cells = <0x01>;
					#size-cells = <0x00>;
					ksz,reset-gpio = <0x41 0x04 0x01>;
					reg = <0x00>;
					dsa,member = <0x00 0x00>;
					ksz,reset-switch;
					ksz,disable-internal-ldo;
					status = "okay";
					linux,phandle = <0x59>;
					phandle = <0x59>;

					ports {
						#address-cells = <0x01>;
						#size-cells = <0x00>;

						port@0 {
							reg = <0x02>;
							label = "ethX1";
						};

						port@1 {
							reg = <0x01>;
							label = "ethX2";
						};

						port@2 {
							reg = <0x03>;
							label = "cpu";
							ethernet = <0x52>;

							fixed-link {
								speed = <0x64>;
								full-duplex;
							};
						};
					};
				};
			};

			slave@4a100200 {
				mac-address = [00 00 00 00 00 00];
			};

			slave@4a100300 {
				mac-address = [00 00 00 00 00 00];
				phy-mode = "rmii";

				fixed-link {
					speed = <0x64>;
					full-duplex;
				};
			};

			cpsw-phy-sel@44e10650 {
				compatible = "ti,am3352-cpsw-phy-sel";
				reg = <0x44e10650 0x04>;
				reg-names = "gmii-sel";
				rmii-clock-ext;
			};
		};

		ocmcram@40300000 {
			compatible = "mmio-sram";
			reg = <0x40300000 0x10000>;
		};

		elm@48080000 {
			compatible = "ti,am3352-elm";
			reg = <0x48080000 0x2000>;
			interrupts = <0x04>;
			ti,hwmods = "elm";
			status = "okay";
		};

		lcdc@4830e000 {
			compatible = "ti,am33xx-tilcdc";
			reg = <0x4830e000 0x1000>;
			interrupt-parent = <0x01>;
			interrupts = <0x24>;
			ti,hwmods = "lcdc";
			status = "disabled";
		};

		tscadc@44e0d000 {
			compatible = "ti,am3359-tscadc";
			reg = <0x44e0d000 0x1000>;
			interrupt-parent = <0x01>;
			interrupts = <0x10>;
			ti,hwmods = "adc_tsc";
			status = "disabled";

			tsc {
				compatible = "ti,am3359-tsc";
			};

			adc {
				#io-channel-cells = <0x01>;
				compatible = "ti,am3359-adc";
			};
		};

		gpmc@50000000 {
			compatible = "ti,am3352-gpmc";
			ti,hwmods = "gpmc";
			ti,no-idle-on-init;
			reg = <0x50000000 0x2000>;
			interrupts = <0x64>;
			dmas = <0x2a 0x34 0x00>;
			dma-names = "rxtx";
			gpmc,num-cs = <0x07>;
			gpmc,num-waitpins = <0x02>;
			#address-cells = <0x02>;
			#size-cells = <0x01>;
			interrupt-controller;
			#interrupt-cells = <0x02>;
			gpio-controller;
			#gpio-cells = <0x02>;
			status = "okay";
			pinctrl-names = "default";
			pinctrl-0 = <0x53 0x54 0x55>;
			num-cs = <0x07>;
			num-waitpins = <0x03>;
			ranges = <0x04 0x00 0x1000000 0x1000000 0x00 0x00 0x4000000 0x1000000>;

			nor@4,0 {
				reg = <0x04 0x00 0x1000000>;
				bank-width = <0x02>;
				gpmc,sync-clk-ps = <0x00>;
				gpmc,cs-on-ns = <0x00>;
				gpmc,cs-rd-off-ns = <0x32>;
				gpmc,cs-wr-off-ns = <0x1e>;
				gpmc,adv-on-ns = <0x00>;
				gpmc,adv-rd-off-ns = <0x00>;
				gpmc,adv-wr-off-ns = <0x00>;
				gpmc,oe-on-ns = <0x00>;
				gpmc,oe-off-ns = <0x32>;
				gpmc,we-on-ns = <0x00>;
				gpmc,we-off-ns = <0x1e>;
				gpmc,rd-cycle-ns = <0x32>;
				gpmc,wr-cycle-ns = <0x1e>;
				gpmc,access-ns = <0x28>;
				gpmc,wr-access-ns = <0x0a>;
				gpmc,wr-data-mux-bus-ns = <0x00>;
				gpmc,cycle2cycle-delay-ns = <0x0a>;
				gpmc,cycle2cycle-samecsen;
				gpmc,cycle2cycle-diffcsen;
				#address-cells = <0x01>;
				#size-cells = <0x01>;
			};

			nor@x0,0 {
				reg = <0x00 0x00 0x1000000>;
				bank-width = <0x02>;
				gpmc,sync-clk-ps = <0x00>;
				gpmc,cs-on-ns = <0x0a>;
				gpmc,cs-rd-off-ns = <0x8c>;
				gpmc,cs-wr-off-ns = <0x64>;
				gpmc,adv-on-ns = <0x00>;
				gpmc,adv-rd-off-ns = <0x00>;
				gpmc,adv-wr-off-ns = <0x00>;
				gpmc,oe-on-ns = <0x0a>;
				gpmc,oe-off-ns = <0x82>;
				gpmc,we-on-ns = <0x01>;
				gpmc,we-off-ns = <0x6e>;
				gpmc,rd-cycle-ns = <0x8c>;
				gpmc,wr-cycle-ns = <0x78>;
				gpmc,access-ns = <0x78>;
				gpmc,wr-access-ns = <0x0a>;
				gpmc,wr-data-mux-bus-ns = <0x00>;
				gpmc,cycle2cycle-delay-ns = <0x00>;
				gpmc,mux-add-data = <0x00>;
				gpmc,clk-activation-ns = <0x00>;
				#address-cells = <0x01>;
				#size-cells = <0x01>;
			};
		};

		sham@53100000 {
			compatible = "ti,omap4-sham";
			ti,hwmods = "sham";
			reg = <0x53100000 0x200>;
			interrupts = <0x6d>;
			dmas = <0x2a 0x24 0x00>;
			dma-names = "rx";
			status = "okay";
		};

		aes@53500000 {
			compatible = "ti,omap4-aes";
			ti,hwmods = "aes";
			reg = <0x53500000 0xa0>;
			interrupts = <0x67>;
			dmas = <0x2a 0x06 0x00 0x2a 0x05 0x00>;
			dma-names = "tx\0rx";
			status = "okay";
		};

		mcasp@48038000 {
			compatible = "ti,am33xx-mcasp-audio";
			ti,hwmods = "mcasp0";
			reg = <0x48038000 0x2000 0x46000000 0x400000>;
			reg-names = "mpu\0dat";
			interrupts = <0x50 0x51>;
			interrupt-names = "tx\0rx";
			status = "disabled";
			dmas = <0x2a 0x08 0x02 0x2a 0x09 0x02>;
			dma-names = "tx\0rx";
		};

		mcasp@4803C000 {
			compatible = "ti,am33xx-mcasp-audio";
			ti,hwmods = "mcasp1";
			reg = <0x4803c000 0x2000 0x46400000 0x400000>;
			reg-names = "mpu\0dat";
			interrupts = <0x52 0x53>;
			interrupt-names = "tx\0rx";
			status = "disabled";
			dmas = <0x2a 0x0a 0x02 0x2a 0x0b 0x02>;
			dma-names = "tx\0rx";
		};

		rng@48310000 {
			compatible = "ti,omap4-rng";
			ti,hwmods = "rng";
			reg = <0x48310000 0x2000>;
			interrupts = <0x6f>;
		};
	};

	fixedregulator@0 {
		compatible = "regulator-fixed";
		regulator-name = "vxe164";
		regulator-min-microvolt = <0x325aa0>;
		regulator-max-microvolt = <0x325aa0>;
		vin-supply = <0x38>;
	};

	fixedregulator@1 {
		compatible = "regulator-fixed";
		regulator-name = "v_sd";
		regulator-min-microvolt = <0x325aa0>;
		regulator-max-microvolt = <0x325aa0>;
		vin-supply = <0x38>;
	};

	wsysinit_init {
		compatible = "wago,sysinit";
		add-sysfs-entries;
		tty,service = "ttyO0";
		tty,rs232-485 = "ttyO1";
		adjtimex,tick = <0x2710>;
		adjtimex,frequency = <0x30d40>;
		board,variant = "pfc200v3";
		pinctrl-names = "default";
		pinctrl-0 = <0x56>;
		dp,reset;
		dp,gpio-rst = <0x41 0x01 0x00>;
	};

	PAC-Operating-Mode-Switch {
		compatible = "gpio-keys";
		#address-cells = <0x01>;
		#size-cells = <0x00>;
		autorepeat;
		status = "okay";

		run {
			label = "RUN";
			gpios = <0x31 0x12 0x01>;
			linux,code = <0x01>;
			linux,input-type = <0x05>;
			debounce-interval = <0x01>;
		};

		stop {
			label = "STOP";
			gpios = <0x31 0x11 0x01>;
			linux,code = <0x02>;
			linux,input-type = <0x05>;
			debounce-interval = <0x01>;
		};

		reset {
			label = "RESET";
			gpios = <0x31 0x10 0x01>;
			linux,code = <0x03>;
			linux,input-type = <0x01>;
			debounce-interval = <0x01>;
		};

		reset_all {
			label = "RESET_ALL";
			gpios = <0x31 0x0f 0x00>;
			linux,code = <0x04>;
			linux,input-type = <0x01>;
			debounce-interval = <0x01>;
		};
	};

	watchdog {
		compatible = "linux,wdt-gpio";
		hw_algo = "toggle";
		hw_margin_ms = <0x640>;
		rt-prio = <0x5b>;
		status = "okay";
		pinctrl-names = "default";
		pinctrl-0 = <0x57>;
		gpio-en = <0x41 0x00 0x01>;
		gpios = <0x31 0x08 0x01>;
	};

	UIO_NVRAM@0x1000000 {
		compatible = "uio_pdrv_genirq";
		uio,map-wc;
		reg = <0x1000000 0x20000>;
	};

	memory {
		device_type = "memory";
		reg = <0x80000000 0x20000000>;
	};

	swcfg_ksz8863 {
		compatible = "swcfg,ksz8863";
		swcfg,mii-bus = <0x58>;
		swcfg,alias = "ksz8863";
		swcfg,cpu_port = <0x02>;
		swcfg,ports = <0x03>;
		swcfg,vlans = <0x10>;
		swcfg,switch = <0x59>;
		status = "okay";
	};

	UIO_DPC31_XINT@0x1000000 {
		compatible = "uio_pdrv_genirq";
		reg = <0x4000000 0x4000>;
		interrupt-parent = <0x42>;
		interrupts = <0x06 0x02>;
	};

	UIO_DPC31_SYNC@0x1000000 {
		compatible = "uio_pdrv_genirq";
		interrupt-parent = <0x39>;
		interrupts = <0x19 0x01>;
	};
};
